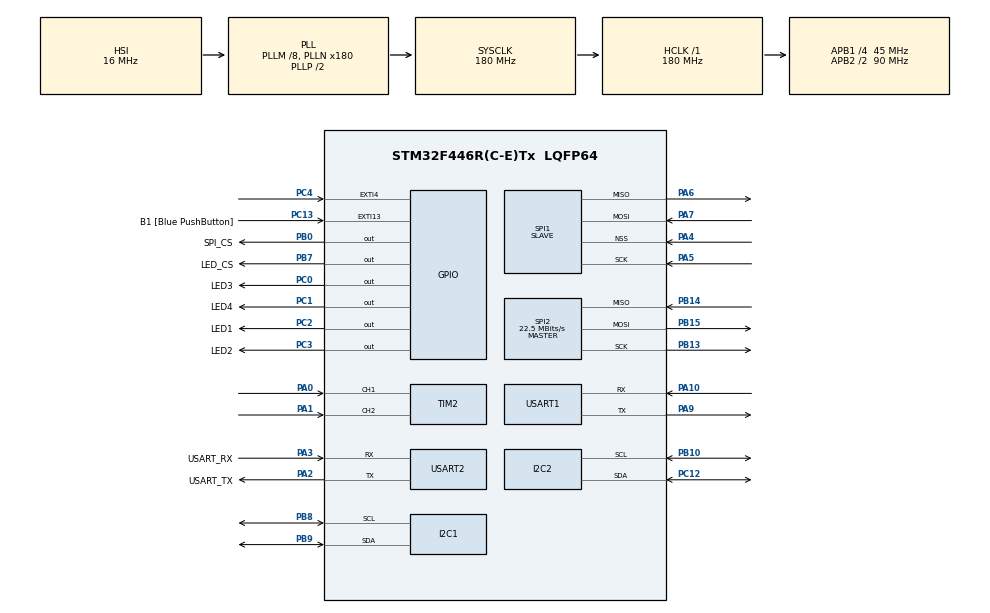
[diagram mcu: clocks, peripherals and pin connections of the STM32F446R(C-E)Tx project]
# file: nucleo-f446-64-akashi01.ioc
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Dma.Request0=USART2_RX
Dma.Request1=USART2_TX
Dma.Request2=USART1_RX
Dma.Request3=USART1_TX
Dma.Request4=SPI1_RX
Dma.Request5=SPI1_TX
Dma.Request6=SPI2_RX
Dma.Request7=SPI2_TX
Dma.SPI1_RX.4.Direction=DMA_PERIPH_TO_MEMORY
Dma.SPI1_RX.4.FIFOMode=DMA_FIFOMODE_DISABLE
Dma.SPI1_RX.4.Instance=DMA2_Stream0
Dma.SPI1_RX.4.MemDataAlignment=DMA_MDATAALIGN_BYTE
Dma.SPI1_RX.4.MemInc=DMA_MINC_ENABLE
Dma.SPI1_RX.4.Mode=DMA_NORMAL
Dma.SPI1_RX.4.PeriphDataAlignment=DMA_PDATAALIGN_BYTE
Dma.SPI1_RX.4.PeriphInc=DMA_PINC_DISABLE
Dma.SPI1_RX.4.Priority=DMA_PRIORITY_LOW
Dma.SPI1_TX.5.Direction=DMA_MEMORY_TO_PERIPH
Dma.SPI1_TX.5.FIFOMode=DMA_FIFOMODE_DISABLE
Dma.SPI1_TX.5.Instance=DMA2_Stream3
Dma.SPI1_TX.5.MemDataAlignment=DMA_MDATAALIGN_BYTE
Dma.SPI1_TX.5.MemInc=DMA_MINC_ENABLE
Dma.SPI1_TX.5.Mode=DMA_NORMAL
Dma.SPI1_TX.5.PeriphDataAlignment=DMA_PDATAALIGN_BYTE
Dma.SPI1_TX.5.PeriphInc=DMA_PINC_DISABLE
Dma.SPI1_TX.5.Priority=DMA_PRIORITY_LOW
Dma.SPI2_RX.6.Direction=DMA_PERIPH_TO_MEMORY
Dma.SPI2_RX.6.FIFOMode=DMA_FIFOMODE_DISABLE
Dma.SPI2_RX.6.Instance=DMA1_Stream3
Dma.SPI2_RX.6.MemDataAlignment=DMA_MDATAALIGN_BYTE
Dma.SPI2_RX.6.MemInc=DMA_MINC_ENABLE
Dma.SPI2_RX.6.Mode=DMA_NORMAL
Dma.SPI2_RX.6.PeriphDataAlignment=DMA_PDATAALIGN_BYTE
Dma.SPI2_RX.6.PeriphInc=DMA_PINC_DISABLE
Dma.SPI2_RX.6.Priority=DMA_PRIORITY_LOW
Dma.SPI2_TX.7.Direction=DMA_MEMORY_TO_PERIPH
Dma.SPI2_TX.7.FIFOMode=DMA_FIFOMODE_DISABLE
Dma.SPI2_TX.7.Instance=DMA1_Stream4
Dma.SPI2_TX.7.MemDataAlignment=DMA_MDATAALIGN_BYTE
Dma.SPI2_TX.7.MemInc=DMA_MINC_ENABLE
Dma.SPI2_TX.7.Mode=DMA_NORMAL
Dma.SPI2_TX.7.PeriphDataAlignment=DMA_PDATAALIGN_BYTE
Dma.SPI2_TX.7.PeriphInc=DMA_PINC_DISABLE
Dma.SPI2_TX.7.Priority=DMA_PRIORITY_LOW
Dma.USART1_RX.2.Direction=DMA_PERIPH_TO_MEMORY
Dma.USART1_RX.2.FIFOMode=DMA_FIFOMODE_DISABLE
Dma.USART1_RX.2.Instance=DMA2_Stream2
Dma.USART1_RX.2.MemDataAlignment=DMA_MDATAALIGN_BYTE
Dma.USART1_RX.2.MemInc=DMA_MINC_ENABLE
Dma.USART1_RX.2.Mode=DMA_NORMAL
Dma.USART1_RX.2.PeriphDataAlignment=DMA_PDATAALIGN_BYTE
Dma.USART1_RX.2.PeriphInc=DMA_PINC_DISABLE
Dma.USART1_RX.2.Priority=DMA_PRIORITY_LOW
Dma.USART1_TX.3.Direction=DMA_MEMORY_TO_PERIPH
Dma.USART1_TX.3.FIFOMode=DMA_FIFOMODE_DISABLE
Dma.USART1_TX.3.Instance=DMA2_Stream7
Dma.USART1_TX.3.MemDataAlignment=DMA_MDATAALIGN_BYTE
Dma.USART1_TX.3.MemInc=DMA_MINC_ENABLE
Dma.USART1_TX.3.Mode=DMA_NORMAL
Dma.USART1_TX.3.PeriphDataAlignment=DMA_PDATAALIGN_BYTE
Dma.USART1_TX.3.PeriphInc=DMA_PINC_DISABLE
Dma.USART1_TX.3.Priority=DMA_PRIORITY_LOW
Dma.USART2_RX.0.Direction=DMA_PERIPH_TO_MEMORY
Dma.USART2_RX.0.FIFOMode=DMA_FIFOMODE_DISABLE
Dma.USART2_RX.0.Instance=DMA1_Stream5
Dma.USART2_RX.0.MemDataAlignment=DMA_MDATAALIGN_BYTE
Dma.USART2_RX.0.MemInc=DMA_MINC_ENABLE
Dma.USART2_RX.0.Mode=DMA_NORMAL
Dma.USART2_RX.0.PeriphDataAlignment=DMA_PDATAALIGN_BYTE
Dma.USART2_RX.0.PeriphInc=DMA_PINC_DISABLE
Dma.USART2_RX.0.Priority=DMA_PRIORITY_LOW
Dma.USART2_TX.1.Direction=DMA_MEMORY_TO_PERIPH
Dma.USART2_TX.1.FIFOMode=DMA_FIFOMODE_DISABLE
Dma.USART2_TX.1.Instance=DMA1_Stream6
Dma.USART2_TX.1.MemDataAlignment=DMA_MDATAALIGN_BYTE
Dma.USART2_TX.1.MemInc=DMA_MINC_ENABLE
Dma.USART2_TX.1.Mode=DMA_NORMAL
Dma.USART2_TX.1.PeriphDataAlignment=DMA_PDATAALIGN_BYTE
Dma.USART2_TX.1.PeriphInc=DMA_PINC_DISABLE
Dma.USART2_TX.1.Priority=DMA_PRIORITY_LOW
FREERTOS.Tasks01=defaultTask,0,256,StartDefaultTask,Default,NULL,Dynamic,NULL,NULL
FREERTOS.configMINIMAL_STACK_SIZE=256
I2C2.OwnAddress=0x39
Mcu.Family=STM32F4
Mcu.Name=STM32F446R(C-E)Tx
Mcu.Package=LQFP64
NVIC.DMA1_Stream3_IRQn=true\:5\:0\:false\:false\:true\:true\:false\:true
NVIC.DMA1_Stream4_IRQn=true\:5\:0\:false\:false\:true\:true\:false\:true
NVIC.DMA1_Stream5_IRQn=true\:5\:0\:false\:false\:true\:true\:false\:true
NVIC.DMA1_Stream6_IRQn=true\:5\:0\:false\:false\:true\:true\:false\:true
NVIC.DMA2_Stream0_IRQn=true\:5\:0\:false\:false\:true\:true\:false\:true
NVIC.DMA2_Stream2_IRQn=true\:5\:0\:false\:false\:true\:true\:false\:true
NVIC.DMA2_Stream3_IRQn=true\:5\:0\:false\:false\:true\:true\:false\:true
NVIC.DMA2_Stream7_IRQn=true\:5\:0\:false\:false\:true\:true\:false\:true
NVIC.I2C1_ER_IRQn=true\:5\:0\:false\:false\:true\:true\:true\:true
NVIC.I2C1_EV_IRQn=true\:5\:0\:false\:false\:true\:true\:true\:true
NVIC.I2C2_ER_IRQn=true\:5\:0\:false\:false\:true\:true\:true\:true
NVIC.I2C2_EV_IRQn=true\:5\:0\:false\:false\:true\:true\:true\:true
NVIC.PriorityGroup=NVIC_PRIORITYGROUP_4
NVIC.SPI1_IRQn=true\:5\:0\:false\:false\:true\:true\:true\:true
NVIC.SPI2_IRQn=true\:5\:0\:false\:false\:true\:true\:true\:true
NVIC.TIM2_IRQn=true\:5\:0\:false\:false\:true\:true\:true\:true
NVIC.TIM8_TRG_COM_TIM14_IRQn=true\:0\:0\:false\:false\:true\:false\:false\:true
NVIC.TimeBase=TIM8_TRG_COM_TIM14_IRQn
NVIC.TimeBaseIP=TIM14
NVIC.USART1_IRQn=true\:5\:0\:false\:false\:true\:true\:true\:true
NVIC.USART2_IRQn=true\:5\:0\:false\:false\:true\:true\:true\:true
PA0-WKUP.Signal=S_TIM2_CH1_ETR
PA1.Signal=S_TIM2_CH2
PA10.Mode=Asynchronous
PA10.Signal=USART1_RX
PA11.Signal=USART1_CTS
PA12.Signal=USART1_RTS
PA13.GPIO_Label=TMS
PA13.Mode=Serial_Wire
PA13.Signal=SYS_JTMS-SWDIO
PA14.GPIO_Label=TCK
PA14.Mode=Serial_Wire
PA14.Signal=SYS_JTCK-SWCLK
PA2.GPIO_Label=USART_TX
PA2.Mode=Asynchronous
PA2.Signal=USART2_TX
PA3.GPIO_Label=USART_RX
PA3.Mode=Asynchronous
PA3.Signal=USART2_RX
PA4.Mode=NSS_Signal_Hard_Input
PA4.Signal=SPI1_NSS
PA5.Mode=Full_Duplex_Slave
PA5.Signal=SPI1_SCK
PA6.Mode=Full_Duplex_Slave
PA6.Signal=SPI1_MISO
PA7.Mode=Full_Duplex_Slave
PA7.Signal=SPI1_MOSI
PA9.Mode=Asynchronous
PA9.Signal=USART1_TX
PB0.GPIO_Label=SPI_CS
PB0.Signal=GPIO_Output
PB10.GPIO_Speed=GPIO_SPEED_FREQ_HIGH
PB10.Mode=I2C
PB10.Signal=I2C2_SCL
PB13.Mode=Full_Duplex_Master
PB13.Signal=SPI2_SCK
PB14.Mode=Full_Duplex_Master
PB14.Signal=SPI2_MISO
PB15.Mode=Full_Duplex_Master
PB15.Signal=SPI2_MOSI
PB3.GPIO_Label=SWO
PB3.Signal=SYS_JTDO-SWO
PB7.GPIO_Label=LED_CS
PB7.Signal=GPIO_Output
PB8.GPIO_Speed=GPIO_SPEED_FREQ_HIGH
PB8.Mode=I2C
PB8.Signal=I2C1_SCL
PB9.GPIO_Speed=GPIO_SPEED_FREQ_HIGH
PB9.Mode=I2C
PB9.Signal=I2C1_SDA
PC0.GPIO_Label=LED3
PC0.Signal=GPIO_Output
PC1.GPIO_Label=LED4
PC1.Signal=GPIO_Output
PC12.GPIO_Speed=GPIO_SPEED_FREQ_HIGH
PC12.Mode=I2C
PC12.Signal=I2C2_SDA
PC13.GPIO_Label=B1 [Blue PushButton]
PC13.GPIO_ModeDefaultEXTI=GPIO_MODE_IT_FALLING
PC13.Signal=GPXTI13
PC14-OSC32_IN.Mode=LSE-External-Oscillator
PC14-OSC32_IN.Signal=RCC_OSC32_IN
PC15-OSC32_OUT.Mode=LSE-External-Oscillator
PC15-OSC32_OUT.Signal=RCC_OSC32_OUT
PC2.GPIO_Label=LED1
PC2.Signal=GPIO_Output
PC3.GPIO_Label=LED2
PC3.Signal=GPIO_Output
PC4.Signal=GPXTI4
PH0-OSC_IN.Mode=HSE-External-Oscillator
PH0-OSC_IN.Signal=RCC_OSC_IN
PH1-OSC_OUT.Mode=HSE-External-Oscillator
PH1-OSC_OUT.Signal=RCC_OSC_OUT
ProjectManager.HeapSize=0x200
ProjectManager.StackSize=0x400
ProjectManager.TargetToolchain=STM32CubeIDE
RCC.48MHZClocksFreq_Value=84000000
RCC.AHBFreq_Value=180000000
RCC.APB1CLKDivider=RCC_HCLK_DIV4
RCC.APB1Freq_Value=45000000
RCC.APB1TimFreq_Value=90000000
RCC.APB2CLKDivider=RCC_HCLK_DIV2
RCC.APB2Freq_Value=90000000
RCC.APB2TimFreq_Value=180000000
RCC.CortexFreq_Value=180000000
RCC.FLatency-AdvancedSettings=FLASH_LATENCY_5
RCC.HCLKFreq_Value=180000000
RCC.HSE_VALUE=8000000
RCC.HSI_VALUE=16000000
RCC.PLLM=8
RCC.PLLN=180
RCC.SYSCLKFreq_VALUE=180000000
RCC.SYSCLKSource=RCC_SYSCLKSOURCE_PLLCLK
RCC.USBFreq_Value=180000000
RCC.VCOOutputFreq_Value=360000000
SH.S_TIM2_CH1_ETR.0=TIM2_CH1,Encoder_Interface
SH.S_TIM2_CH2.0=TIM2_CH2,Encoder_Interface
SPI1.Direction=SPI_DIRECTION_2LINES
SPI1.Mode=SPI_MODE_SLAVE
SPI1.VirtualNSS=VM_NSSHARD
SPI1.VirtualType=VM_SLAVE
SPI2.CalculateBaudRate=22.5 MBits/s
SPI2.Direction=SPI_DIRECTION_2LINES
SPI2.Mode=SPI_MODE_MASTER
SPI2.VirtualType=VM_MASTER
USART1.VirtualMode=VM_ASYNC
USART2.VirtualMode=VM_ASYNC
VP_FREERTOS_VS_CMSIS_V1.Mode=CMSIS_V1
VP_SYS_VS_tim14.Mode=TIM14
board=NUCLEO-F446RE

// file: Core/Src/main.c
/* USER CODE BEGIN Header */
/**
  ******************************************************************************
  * @file           : main.c
  * @brief          : Main program body
  ******************************************************************************
  * @attention
  *
  * <h2><center>&copy; Copyright (c) 2020 STMicroelectronics.
  * All rights reserved.</center></h2>
  *
  * This software component is licensed by ST under BSD 3-Clause license,
  * the "License"; You may not use this file except in compliance with the
  * License. You may obtain a copy of the License at:
  *                        opensource.org/licenses/BSD-3-Clause
  *
  ******************************************************************************
  */
/* USER CODE END Header */

#include "main.h"
#include "cmsis_os.h"

/* USER CODE BEGIN Includes */
#include "murasaki_platform.hpp"

/* USER CODE END Includes */

I2C_HandleTypeDef hi2c1;
I2C_HandleTypeDef hi2c2;

SPI_HandleTypeDef hspi1;
SPI_HandleTypeDef hspi2;
DMA_HandleTypeDef hdma_spi1_rx;
DMA_HandleTypeDef hdma_spi1_tx;
DMA_HandleTypeDef hdma_spi2_rx;
DMA_HandleTypeDef hdma_spi2_tx;

TIM_HandleTypeDef htim2;

UART_HandleTypeDef huart1;
UART_HandleTypeDef huart2;
DMA_HandleTypeDef hdma_usart1_rx;
DMA_HandleTypeDef hdma_usart1_tx;
DMA_HandleTypeDef hdma_usart2_rx;
DMA_HandleTypeDef hdma_usart2_tx;

osThreadId defaultTaskHandle;

void SystemClock_Config(void);
static void MX_GPIO_Init(void);
static void MX_DMA_Init(void);
static void MX_USART2_UART_Init(void);
static void MX_I2C1_Init(void);
static void MX_I2C2_Init(void);
static void MX_SPI1_Init(void);
static void MX_SPI2_Init(void);
static void MX_USART1_UART_Init(void);
static void MX_TIM2_Init(void);
void StartDefaultTask(void const * argument);

int main(void)
{

  /* MCU Configuration--------------------------------------------------------*/

  /* Reset of all peripherals, Initializes the Flash interface and the Systick. */
  HAL_Init();

  /* Configure the system clock */
  SystemClock_Config();

  /* Initialize all configured peripherals */
  MX_GPIO_Init();
  MX_DMA_Init();
  MX_USART2_UART_Init();
  MX_I2C1_Init();
  MX_I2C2_Init();
  MX_SPI1_Init();
  MX_SPI2_Init();
  MX_USART1_UART_Init();
  MX_TIM2_Init();

  /* Create the thread(s) */
  /* definition and creation of defaultTask */
  osThreadDef(defaultTask, StartDefaultTask, osPriorityNormal, 0, 256);
  defaultTaskHandle = osThreadCreate(osThread(defaultTask), NULL);

  /* Start scheduler */
  osKernelStart();

  /* We should never get here as control is now taken by the scheduler */
  /* Infinite loop */
  while (1)
  {

  }
}

void SystemClock_Config(void)
{
  RCC_OscInitTypeDef RCC_OscInitStruct = {0};
  RCC_ClkInitTypeDef RCC_ClkInitStruct = {0};

  /** Configure the main internal regulator output voltage
  */
  __HAL_RCC_PWR_CLK_ENABLE();
  __HAL_PWR_VOLTAGESCALING_CONFIG(PWR_REGULATOR_VOLTAGE_SCALE1);
  /** Initializes the CPU, AHB and APB busses clocks
  */
  RCC_OscInitStruct.OscillatorType = RCC_OSCILLATORTYPE_HSI;
  RCC_OscInitStruct.HSIState = RCC_HSI_ON;
  RCC_OscInitStruct.HSICalibrationValue = RCC_HSICALIBRATION_DEFAULT;
  RCC_OscInitStruct.PLL.PLLState = RCC_PLL_ON;
  RCC_OscInitStruct.PLL.PLLSource = RCC_PLLSOURCE_HSI;
  RCC_OscInitStruct.PLL.PLLM = 8;
  RCC_OscInitStruct.PLL.PLLN = 180;
  RCC_OscInitStruct.PLL.PLLP = RCC_PLLP_DIV2;
  RCC_OscInitStruct.PLL.PLLQ = 2;
  RCC_OscInitStruct.PLL.PLLR = 2;
  if (HAL_RCC_OscConfig(&RCC_OscInitStruct) != HAL_OK)
  {
    Error_Handler();
  }
  /** Activate the Over-Drive mode
  */
  if (HAL_PWREx_EnableOverDrive() != HAL_OK)
  {
    Error_Handler();
  }
  /** Initializes the CPU, AHB and APB busses clocks
  */
  RCC_ClkInitStruct.ClockType = RCC_CLOCKTYPE_HCLK|RCC_CLOCKTYPE_SYSCLK
                              |RCC_CLOCKTYPE_PCLK1|RCC_CLOCKTYPE_PCLK2;
  RCC_ClkInitStruct.SYSCLKSource = RCC_SYSCLKSOURCE_PLLCLK;
  RCC_ClkInitStruct.AHBCLKDivider = RCC_SYSCLK_DIV1;
  RCC_ClkInitStruct.APB1CLKDivider = RCC_HCLK_DIV4;
  RCC_ClkInitStruct.APB2CLKDivider = RCC_HCLK_DIV2;

  if (HAL_RCC_ClockConfig(&RCC_ClkInitStruct, FLASH_LATENCY_5) != HAL_OK)
  {
    Error_Handler();
  }
}

static void MX_I2C1_Init(void)
{

  hi2c1.Instance = I2C1;
  hi2c1.Init.ClockSpeed = 100000;
  hi2c1.Init.DutyCycle = I2C_DUTYCYCLE_2;
  hi2c1.Init.OwnAddress1 = 0;
  hi2c1.Init.AddressingMode = I2C_ADDRESSINGMODE_7BIT;
  hi2c1.Init.DualAddressMode = I2C_DUALADDRESS_DISABLE;
  hi2c1.Init.OwnAddress2 = 0;
  hi2c1.Init.GeneralCallMode = I2C_GENERALCALL_DISABLE;
  hi2c1.Init.NoStretchMode = I2C_NOSTRETCH_DISABLE;
  if (HAL_I2C_Init(&hi2c1) != HAL_OK)
  {
    Error_Handler();
  }

}

static void MX_I2C2_Init(void)
{

  hi2c2.Instance = I2C2;
  hi2c2.Init.ClockSpeed = 100000;
  hi2c2.Init.DutyCycle = I2C_DUTYCYCLE_2;
  hi2c2.Init.OwnAddress1 = 114;
  hi2c2.Init.AddressingMode = I2C_ADDRESSINGMODE_7BIT;
  hi2c2.Init.DualAddressMode = I2C_DUALADDRESS_DISABLE;
  hi2c2.Init.OwnAddress2 = 0;
  hi2c2.Init.GeneralCallMode = I2C_GENERALCALL_DISABLE;
  hi2c2.Init.NoStretchMode = I2C_NOSTRETCH_DISABLE;
  if (HAL_I2C_Init(&hi2c2) != HAL_OK)
  {
    Error_Handler();
  }

}

static void MX_SPI1_Init(void)
{

  /* SPI1 parameter configuration*/
  hspi1.Instance = SPI1;
  hspi1.Init.Mode = SPI_MODE_SLAVE;
  hspi1.Init.Direction = SPI_DIRECTION_2LINES;
  hspi1.Init.DataSize = SPI_DATASIZE_8BIT;
  hspi1.Init.CLKPolarity = SPI_POLARITY_LOW;
  hspi1.Init.CLKPhase = SPI_PHASE_1EDGE;
  hspi1.Init.NSS = SPI_NSS_HARD_INPUT;
  hspi1.Init.FirstBit = SPI_FIRSTBIT_MSB;
  hspi1.Init.TIMode = SPI_TIMODE_DISABLE;
  hspi1.Init.CRCCalculation = SPI_CRCCALCULATION_DISABLE;
  hspi1.Init.CRCPolynomial = 10;
  if (HAL_SPI_Init(&hspi1) != HAL_OK)
  {
    Error_Handler();
  }

}

static void MX_SPI2_Init(void)
{

  /* SPI2 parameter configuration*/
  hspi2.Instance = SPI2;
  hspi2.Init.Mode = SPI_MODE_MASTER;
  hspi2.Init.Direction = SPI_DIRECTION_2LINES;
  hspi2.Init.DataSize = SPI_DATASIZE_8BIT;
  hspi2.Init.CLKPolarity = SPI_POLARITY_LOW;
  hspi2.Init.CLKPhase = SPI_PHASE_1EDGE;
  hspi2.Init.NSS = SPI_NSS_SOFT;
  hspi2.Init.BaudRatePrescaler = SPI_BAUDRATEPRESCALER_2;
  hspi2.Init.FirstBit = SPI_FIRSTBIT_MSB;
  hspi2.Init.TIMode = SPI_TIMODE_DISABLE;
  hspi2.Init.CRCCalculation = SPI_CRCCALCULATION_DISABLE;
  hspi2.Init.CRCPolynomial = 10;
  if (HAL_SPI_Init(&hspi2) != HAL_OK)
  {
    Error_Handler();
  }

}

static void MX_TIM2_Init(void)
{

  TIM_Encoder_InitTypeDef sConfig = {0};
  TIM_MasterConfigTypeDef sMasterConfig = {0};

  htim2.Instance = TIM2;
  htim2.Init.Prescaler = 0;
  htim2.Init.CounterMode = TIM_COUNTERMODE_UP;
  htim2.Init.Period = 0;
  htim2.Init.ClockDivision = TIM_CLOCKDIVISION_DIV1;
  htim2.Init.AutoReloadPreload = TIM_AUTORELOAD_PRELOAD_DISABLE;
  sConfig.EncoderMode = TIM_ENCODERMODE_TI1;
  sConfig.IC1Polarity = TIM_ICPOLARITY_RISING;
  sConfig.IC1Selection = TIM_ICSELECTION_DIRECTTI;
  sConfig.IC1Prescaler = TIM_ICPSC_DIV1;
  sConfig.IC1Filter = 0;
  sConfig.IC2Polarity = TIM_ICPOLARITY_RISING;
  sConfig.IC2Selection = TIM_ICSELECTION_DIRECTTI;
  sConfig.IC2Prescaler = TIM_ICPSC_DIV1;
  sConfig.IC2Filter = 0;
  if (HAL_TIM_Encoder_Init(&htim2, &sConfig) != HAL_OK)
  {
    Error_Handler();
  }
  sMasterConfig.MasterOutputTrigger = TIM_TRGO_RESET;
  sMasterConfig.MasterSlaveMode = TIM_MASTERSLAVEMODE_DISABLE;
  if (HAL_TIMEx_MasterConfigSynchronization(&htim2, &sMasterConfig) != HAL_OK)
  {
    Error_Handler();
  }

}

static void MX_USART1_UART_Init(void)
{

  huart1.Instance = USART1;
  huart1.Init.BaudRate = 115200;
  huart1.Init.WordLength = UART_WORDLENGTH_8B;
  huart1.Init.StopBits = UART_STOPBITS_1;
  huart1.Init.Parity = UART_PARITY_NONE;
  huart1.Init.Mode = UART_MODE_TX_RX;
  huart1.Init.HwFlowCtl = UART_HWCONTROL_NONE;
  huart1.Init.OverSampling = UART_OVERSAMPLING_16;
  if (HAL_UART_Init(&huart1) != HAL_OK)
  {
    Error_Handler();
  }

}

static void MX_USART2_UART_Init(void)
{

  huart2.Instance = USART2;
  huart2.Init.BaudRate = 115200;
  huart2.Init.WordLength = UART_WORDLENGTH_8B;
  huart2.Init.StopBits = UART_STOPBITS_1;
  huart2.Init.Parity = UART_PARITY_NONE;
  huart2.Init.Mode = UART_MODE_TX_RX;
  huart2.Init.HwFlowCtl = UART_HWCONTROL_NONE;
  huart2.Init.OverSampling = UART_OVERSAMPLING_16;
  if (HAL_UART_Init(&huart2) != HAL_OK)
  {
    Error_Handler();
  }

}

static void MX_DMA_Init(void)
{

  /* DMA controller clock enable */
  __HAL_RCC_DMA1_CLK_ENABLE();
  __HAL_RCC_DMA2_CLK_ENABLE();

  /* DMA interrupt init */
  /* DMA1_Stream3_IRQn interrupt configuration */
  HAL_NVIC_SetPriority(DMA1_Stream3_IRQn, 5, 0);
  HAL_NVIC_EnableIRQ(DMA1_Stream3_IRQn);
  /* DMA1_Stream4_IRQn interrupt configuration */
  HAL_NVIC_SetPriority(DMA1_Stream4_IRQn, 5, 0);
  HAL_NVIC_EnableIRQ(DMA1_Stream4_IRQn);
  /* DMA1_Stream5_IRQn interrupt configuration */
  HAL_NVIC_SetPriority(DMA1_Stream5_IRQn, 5, 0);
  HAL_NVIC_EnableIRQ(DMA1_Stream5_IRQn);
  /* DMA1_Stream6_IRQn interrupt configuration */
  HAL_NVIC_SetPriority(DMA1_Stream6_IRQn, 5, 0);
  HAL_NVIC_EnableIRQ(DMA1_Stream6_IRQn);
  /* DMA2_Stream0_IRQn interrupt configuration */
  HAL_NVIC_SetPriority(DMA2_Stream0_IRQn, 5, 0);
  HAL_NVIC_EnableIRQ(DMA2_Stream0_IRQn);
  /* DMA2_Stream2_IRQn interrupt configuration */
  HAL_NVIC_SetPriority(DMA2_Stream2_IRQn, 5, 0);
  HAL_NVIC_EnableIRQ(DMA2_Stream2_IRQn);
  /* DMA2_Stream3_IRQn interrupt configuration */
  HAL_NVIC_SetPriority(DMA2_Stream3_IRQn, 5, 0);
  HAL_NVIC_EnableIRQ(DMA2_Stream3_IRQn);
  /* DMA2_Stream7_IRQn interrupt configuration */
  HAL_NVIC_SetPriority(DMA2_Stream7_IRQn, 5, 0);
  HAL_NVIC_EnableIRQ(DMA2_Stream7_IRQn);

}

static void MX_GPIO_Init(void)
{
  GPIO_InitTypeDef GPIO_InitStruct = {0};

  /* GPIO Ports Clock Enable */
  __HAL_RCC_GPIOC_CLK_ENABLE();
  __HAL_RCC_GPIOH_CLK_ENABLE();
  __HAL_RCC_GPIOA_CLK_ENABLE();
  __HAL_RCC_GPIOB_CLK_ENABLE();

  /*Configure GPIO pin Output Level */
  HAL_GPIO_WritePin(GPIOC, LED3_Pin|LED4_Pin|LED1_Pin|LED2_Pin, GPIO_PIN_RESET);

  /*Configure GPIO pin Output Level */
  HAL_GPIO_WritePin(GPIOB, SPI_CS_Pin|LED_CS_Pin, GPIO_PIN_RESET);

  /*Configure GPIO pin : B1_Pin */
  GPIO_InitStruct.Pin = B1_Pin;
  GPIO_InitStruct.Mode = GPIO_MODE_IT_FALLING;
  GPIO_InitStruct.Pull = GPIO_NOPULL;
  HAL_GPIO_Init(B1_GPIO_Port, &GPIO_InitStruct);

  /*Configure GPIO pins : LED3_Pin LED4_Pin LED1_Pin LED2_Pin */
  GPIO_InitStruct.Pin = LED3_Pin|LED4_Pin|LED1_Pin|LED2_Pin;
  GPIO_InitStruct.Mode = GPIO_MODE_OUTPUT_PP;
  GPIO_InitStruct.Pull = GPIO_NOPULL;
  GPIO_InitStruct.Speed = GPIO_SPEED_FREQ_LOW;
  HAL_GPIO_Init(GPIOC, &GPIO_InitStruct);

  /*Configure GPIO pin : PC4 */
  GPIO_InitStruct.Pin = GPIO_PIN_4;
  GPIO_InitStruct.Mode = GPIO_MODE_IT_RISING;
  GPIO_InitStruct.Pull = GPIO_NOPULL;
  HAL_GPIO_Init(GPIOC, &GPIO_InitStruct);

  /*Configure GPIO pins : SPI_CS_Pin LED_CS_Pin */
  GPIO_InitStruct.Pin = SPI_CS_Pin|LED_CS_Pin;
  GPIO_InitStruct.Mode = GPIO_MODE_OUTPUT_PP;
  GPIO_InitStruct.Pull = GPIO_NOPULL;
  GPIO_InitStruct.Speed = GPIO_SPEED_FREQ_LOW;
  HAL_GPIO_Init(GPIOB, &GPIO_InitStruct);

}

void StartDefaultTask(void const * argument)
{
  /* USER CODE BEGIN 5 */
  InitPlatform();
  ExecPlatform();
  /* Infinite loop */
  for(;;)
  {
    osDelay(1);
  }
  /* USER CODE END 5 */
}

 /**
  * @brief  Period elapsed callback in non blocking mode
  * @note   This function is called  when TIM14 interrupt took place, inside
  * HAL_TIM_IRQHandler(). It makes a direct call to HAL_IncTick() to increment
  * a global variable "uwTick" used as application time base.
  * @param  htim : TIM handle
  * @retval None
  */
void HAL_TIM_PeriodElapsedCallback(TIM_HandleTypeDef *htim)
{
  if (htim->Instance == TIM14) {
    HAL_IncTick();
  }
}

void Error_Handler(void)
{
}

#ifdef  USE_FULL_ASSERT
/**
  * @brief  Reports the name of the source file and the source line number
  *         where the assert_param error has occurred.
  * @param  file: pointer to the source file name
  * @param  line: assert_param error line source number
  * @retval None
  */
void assert_failed(uint8_t *file, uint32_t line)
{
  /* USER CODE BEGIN 6 */
  /* User can add his own implementation to report the file name and line number,
     tex: printf("Wrong parameters value: file %s on line %d\r\n", file, line) */
    CustomAssertFailed(file, line);
  /* USER CODE END 6 */
}
#endif /* USE_FULL_ASSERT */

/************************ (C) COPYRIGHT STMicroelectronics *****END OF FILE****/
